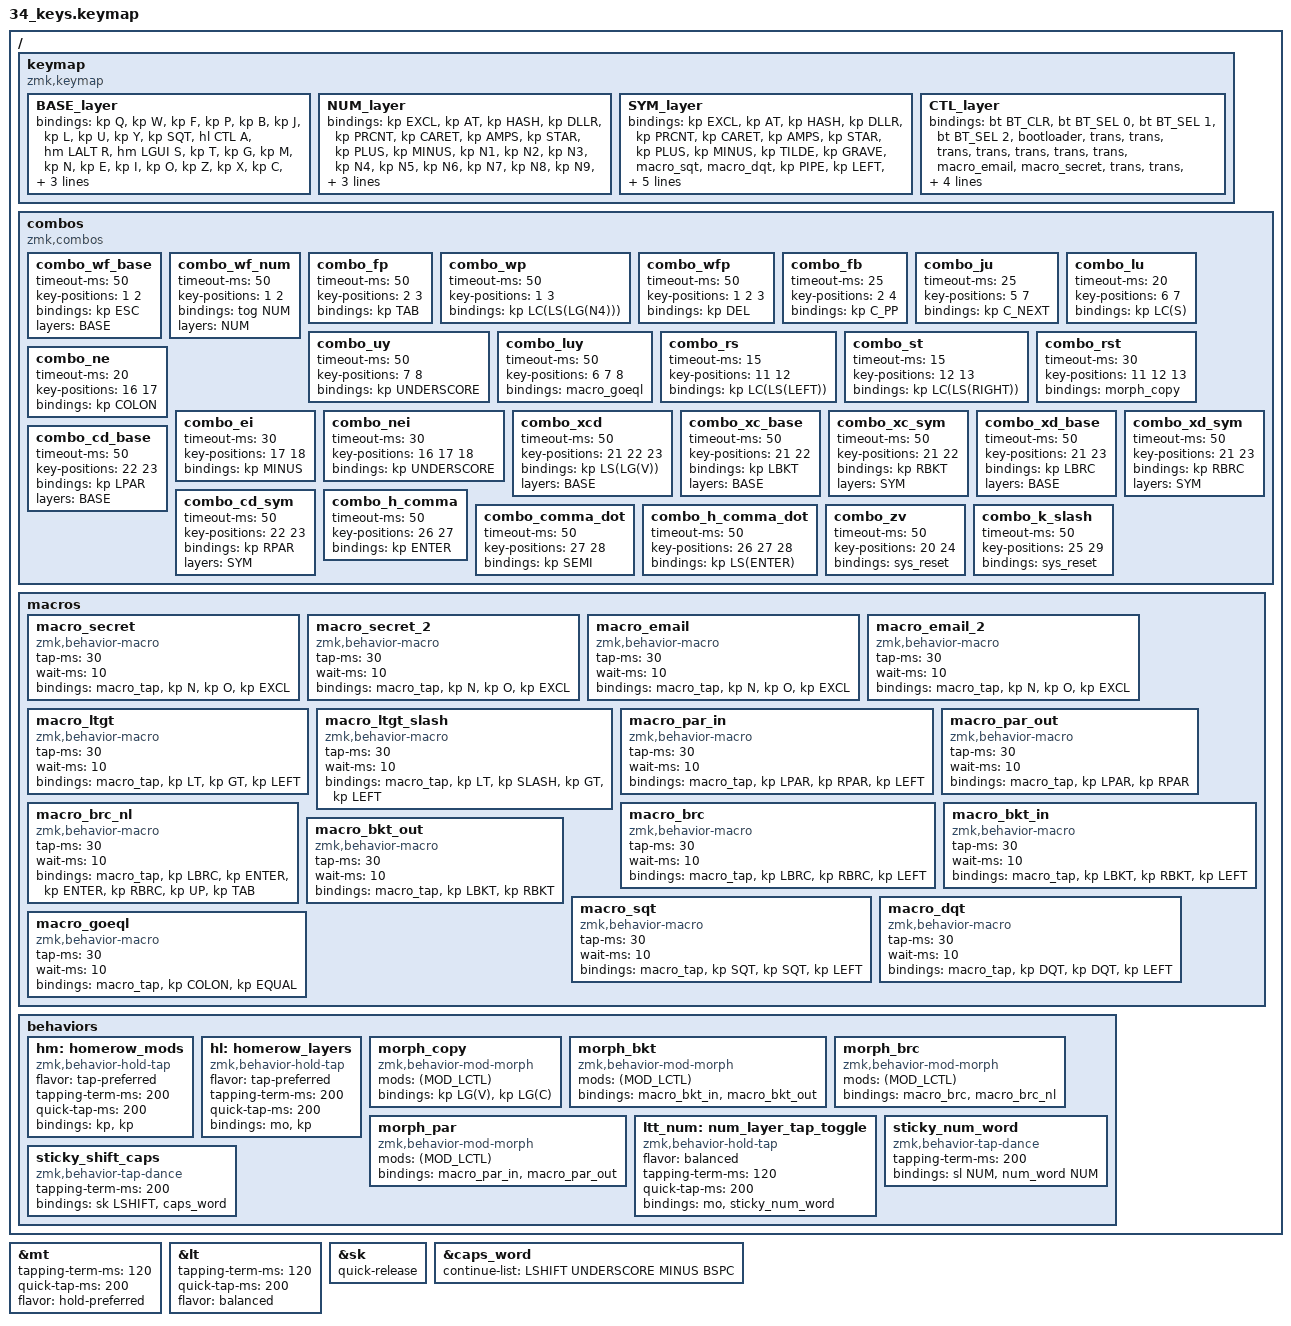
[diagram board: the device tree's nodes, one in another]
// vim: textwidth=0

/*
 * Copyright (c) 2021 The ZMK Contributors
 *
 * SPDX-License-Identifier: MIT
 */

#include <behaviors.dtsi>
#include <behaviors/num_word.dtsi>
#include <dt-bindings/zmk/keys.h>
#include <dt-bindings/zmk/bt.h>

#define BASE 0
#define NUM  1
#define SYM  2
#define CTL  3

&mt {
  tapping-term-ms = <120>;
  quick-tap-ms = <200>;
  flavor = "hold-preferred";
};

&lt {
  tapping-term-ms = <120>;
  quick-tap-ms = <200>;
  flavor = "balanced";
};

&sk {
  quick-release;  // prevent TWo caps when using sk SHIFT
};

&caps_word {
  continue-list = <LSHIFT UNDERSCORE MINUS BSPC>;
};

/*
30-key challenges
ctrl-z
shift-v -> solved by combo
ctrl-v -> not used often enough?
typing zmk lol
*/

/ {
  keymap {
    compatible = "zmk,keymap";

    BASE_layer {
      bindings = <
        // row 1
        &kp Q
        &kp W
        &kp F
        &kp P
        &kp B

        &kp J
        &kp L
        &kp U
        &kp Y
        &kp SQT

        // row 2
        &hl CTL A
        &hm LALT R
        &hm LGUI S
        &kp T
        &kp G

        &kp M
        &kp N
        &kp E
        &kp I
        &kp O

        // row 3
        &kp Z // dropped on 30-key
        &kp X
        &kp C
        &kp D
        &kp V // dropped on 30-key


        // &trans
        &kp K // dropped on 30-key
        &kp H
        &kp COMMA
        &kp DOT
        &kp SLASH // dropped on 30-key

        // row thumbs
        &sticky_shift_caps
        &mt LCTRL BSPC

        &lt SYM SPACE
        &ltt_num NUM NUM
      >;
    };

    NUM_layer {
      bindings = <
        // row 1
        &kp EXCL
        &kp AT
        &kp HASH
        &kp DLLR
        &kp PRCNT

        &kp CARET
        &kp AMPS
        &kp STAR
        &kp PLUS
        &kp MINUS

        // row 2
        &kp N1
        &kp N2
        &kp N3
        &kp N4
        &kp N5

        &kp N6
        &kp N7
        &kp N8
        &kp N9
        &kp N0

        // row 3
        &trans
        &trans
        &trans
        &trans
        &trans

        &trans
        &trans
        &trans
        &trans
        &trans

        // row thumbs
        &trans
        &trans
        &trans
        &trans // being held
      >;
    };

    SYM_layer {
      bindings = <
        // row 1
        &kp EXCL
        &kp AT
        &kp HASH
        &kp DLLR
        &kp PRCNT

        &kp CARET
        &kp AMPS
        &kp STAR
        &kp PLUS
        &kp MINUS

        // row 2
        &kp TILDE
        &kp GRAVE
        &macro_sqt
        &macro_dqt
        &kp PIPE

        &kp LEFT
        &kp DOWN
        &kp UP
        &kp RIGHT
        &kp BSLH

        // row 3
        &trans // dropped on 30-key
        &morph_bkt
        &morph_brc
        &morph_par
        &kp SEMI // dropped on 30-key

        &trans // dropped on 30-key
        &kp EQUAL
        &macro_ltgt
        &macro_ltgt_slash
        &trans // dropped on 30-key

        // row thumbs
        &trans
        &trans
        &trans // being held
        &trans
      >;
    };

    CTL_layer {
      bindings = <
        // row 1
        &bt BT_CLR
        &bt BT_SEL 0
        &bt BT_SEL 1
        &bt BT_SEL 2
        &bootloader

        &trans
        &trans
        &trans
        &trans
        &trans

        // row 2
        &trans
        &trans
        &macro_email
        &macro_secret
        &trans

        &trans
        &bt BT_PRV
        &bt BT_NXT
        &trans
        &trans

        // row 3
        &trans
        &trans
        &macro_email_2
        &macro_secret_2
        &trans

        &trans
        &trans
        &trans
        &trans
        &trans

        // row thumbs
        &trans
        &trans
        &trans
        &trans
      >;
    };
  };

  combos {
    compatible = "zmk,combos";
    // row 1
    combo_wf_base {
      timeout-ms = <50>;
      key-positions = <1 2>;
      bindings = <&kp ESC>;
      layers = <BASE>;
    };
    combo_wf_num {
      timeout-ms = <50>;
      key-positions = <1 2>;
      bindings = <&tog NUM>;
      layers = <NUM>;
    };
    combo_fp {
      timeout-ms = <50>;
      key-positions = <2 3>;
      bindings = <&kp TAB>;
    };
    combo_wp {
      timeout-ms = <50>;
      key-positions = <1 3>;
      bindings = <&kp LC(LS(LG(N4)))>; // screenshots
    };
    combo_wfp {
      timeout-ms = <50>;
      key-positions = <1 2 3>;
      bindings = <&kp DEL>;
    };
    combo_fb {
      timeout-ms = <25>;
      key-positions = <2 4>;
      bindings = <&kp C_PP>;
    };
    combo_ju {
      timeout-ms = <25>;
      key-positions = <5 7>;
      bindings = <&kp C_NEXT>;
    };
    combo_lu {
      timeout-ms = <20>;
      key-positions = <6 7>;
      bindings = <&kp LC(S)>;
    };
    combo_uy {
      timeout-ms = <50>;
      key-positions = <7 8>;
      bindings = <&kp UNDERSCORE>;
    };
    combo_luy {
      timeout-ms = <50>;
      key-positions = <6 7 8>;
      bindings = <&macro_goeql>;
    };
    // row 2
    combo_rs {
      timeout-ms = <15>;
      key-positions = <11 12>;
      bindings = <&kp LC(LS(LEFT))>;
    };
    combo_st {
      timeout-ms = <15>;
      key-positions = <12 13>;
      bindings = <&kp LC(LS(RIGHT))>;
    };
    combo_rst {
      timeout-ms = <30>;
      key-positions = <11 12 13>;
      bindings = <&morph_copy>;
    };
    combo_ne {
      timeout-ms = <20>;
      key-positions = <16 17>;
      bindings = <&kp COLON>;
    };
    combo_ei {
      timeout-ms = <30>;
      key-positions = <17 18>;
      bindings = <&kp MINUS>;
    };
    combo_nei {
      timeout-ms = <30>;
      key-positions = <16 17 18>;
      bindings = <&kp UNDERSCORE>;
    };
    // row 3
    combo_xcd { 
      timeout-ms = <50>;
      key-positions = <21 22 23>;
      bindings = <&kp LS(LG(V))>; // clipboard selection
      layers = <BASE>;
    };
    // singles of each [{()}]
    combo_xc_base {
      timeout-ms = <50>;
      key-positions = <21 22>;
      bindings = <&kp LBKT>;
      layers = <BASE>;
    };
    combo_xc_sym {
      timeout-ms = <50>;
      key-positions = <21 22>;
      bindings = <&kp RBKT>;
      layers = <SYM>;
    };
    combo_xd_base {
      timeout-ms = <50>;
      key-positions = <21 23>;
      bindings = <&kp LBRC>;
      layers = <BASE>;
    };
    combo_xd_sym {
      timeout-ms = <50>;
      key-positions = <21 23>;
      bindings = <&kp RBRC>;
      layers = <SYM>;
    };
    combo_cd_base {
      timeout-ms = <50>;
      key-positions = <22 23>;
      bindings = <&kp LPAR>;
      layers = <BASE>;
    };
    combo_cd_sym {
      timeout-ms = <50>;
      key-positions = <22 23>;
      bindings = <&kp RPAR>;
      layers = <SYM>;
    };
    combo_h_comma {
      timeout-ms = <50>;
      key-positions = <26 27>;
      bindings = <&kp ENTER>;
    };
    combo_comma_dot {
      timeout-ms = <50>;
      key-positions = <27 28>;
      bindings = <&kp SEMI>;
    };
    combo_h_comma_dot {
      timeout-ms = <50>;
      key-positions = <26 27 28>;
      bindings = <&kp LS(ENTER)>;
    };
    // resets
    combo_zv {
      timeout-ms = <50>;
      key-positions = <20 24>;
      bindings = <&sys_reset>;
    };
    combo_k_slash {
      timeout-ms = <50>;
      key-positions = <25 29>;
      bindings = <&sys_reset>;
    };
  };

  macros {
    macro_secret: macro_secret {
      compatible = "zmk,behavior-macro";
      tap-ms = <30>;
      wait-ms = <10>;
      #binding-cells = <0>;
      bindings = <&macro_tap &kp N &kp O &kp EXCL>;
    };
    macro_secret_2: macro_secret_2 {
      compatible = "zmk,behavior-macro";
      tap-ms = <30>;
      wait-ms = <10>;
      #binding-cells = <0>;
      bindings = <&macro_tap &kp N &kp O &kp EXCL>;
    };
    macro_email: macro_email {
      compatible = "zmk,behavior-macro";
      tap-ms = <30>;
      wait-ms = <10>;
      #binding-cells = <0>;
      bindings = <&macro_tap &kp N &kp O &kp EXCL>;
    };
    macro_email_2: macro_email_2 {
      compatible = "zmk,behavior-macro";
      tap-ms = <30>;
      wait-ms = <10>;
      #binding-cells = <0>;
      bindings = <&macro_tap &kp N &kp O &kp EXCL>;
    };
    macro_ltgt: macro_ltgt {
      compatible = "zmk,behavior-macro";
      tap-ms = <30>;
      wait-ms = <10>;
      #binding-cells = <0>;
      bindings = <&macro_tap &kp LT &kp GT &kp LEFT>;
    };
    macro_ltgt_slash: macro_ltgt_slash {
      compatible = "zmk,behavior-macro";
      tap-ms = <30>;
      wait-ms = <10>;
      #binding-cells = <0>;
      bindings = <&macro_tap &kp LT &kp SLASH &kp GT &kp LEFT>;
    };
    macro_par_in: macro_par_in {
      compatible = "zmk,behavior-macro";
      tap-ms = <30>;
      wait-ms = <10>;
      #binding-cells = <0>;
      bindings = <&macro_tap &kp LPAR &kp RPAR &kp LEFT>;
    };
    macro_par_out: macro_par_out {
      compatible = "zmk,behavior-macro";
      tap-ms = <30>;
      wait-ms = <10>;
      #binding-cells = <0>;
      bindings = <&macro_tap &kp LPAR &kp RPAR>;
    };
    macro_brc: macro_brc {
      compatible = "zmk,behavior-macro";
      tap-ms = <30>;
      wait-ms = <10>;
      #binding-cells = <0>;
      bindings = <&macro_tap &kp LBRC &kp RBRC &kp LEFT>;
    };
    macro_brc_nl: macro_brc_nl {
      compatible = "zmk,behavior-macro";
      tap-ms = <30>;
      wait-ms = <10>;
      #binding-cells = <0>;
      bindings = <&macro_tap &kp LBRC &kp ENTER &kp ENTER &kp RBRC &kp UP &kp TAB>;
    };
    macro_bkt_in: macro_bkt_in {
      compatible = "zmk,behavior-macro";
      tap-ms = <30>;
      wait-ms = <10>;
      #binding-cells = <0>;
      bindings = <&macro_tap &kp LBKT &kp RBKT &kp LEFT>;
    };
    macro_bkt_out: macro_bkt_out {
      compatible = "zmk,behavior-macro";
      tap-ms = <30>;
      wait-ms = <10>;
      #binding-cells = <0>;
      bindings = <&macro_tap &kp LBKT &kp RBKT>;
    };
    macro_sqt: macro_sqt {
      compatible = "zmk,behavior-macro";
      tap-ms = <30>;
      wait-ms = <10>;
      #binding-cells = <0>;
      bindings = <&macro_tap &kp SQT &kp SQT &kp LEFT>;
    };
    macro_dqt: macro_dqt {
      compatible = "zmk,behavior-macro";
      tap-ms = <30>;
      wait-ms = <10>;
      #binding-cells = <0>;
      bindings = <&macro_tap &kp DQT &kp DQT &kp LEFT>;
    };
    macro_goeql: macro_goeql {
      compatible = "zmk,behavior-macro";
      tap-ms = <30>;
      wait-ms = <10>;
      #binding-cells = <0>;
      bindings = <&macro_tap &kp COLON &kp EQUAL>;
    };
  };

  behaviors {
    hm: homerow_mods {
      compatible = "zmk,behavior-hold-tap";
      flavor = "tap-preferred";
      tapping-term-ms = <200>;
      quick-tap-ms = <200>;
      #binding-cells = <2>;
      bindings = <&kp>, <&kp>;
    };
    hl: homerow_layers {
      compatible = "zmk,behavior-hold-tap";
      flavor = "tap-preferred";
      tapping-term-ms = <200>;
      quick-tap-ms = <200>;
      #binding-cells = <2>;
      bindings = <&mo>, <&kp>;
    };
    morph_copy: morph_copy {
      compatible = "zmk,behavior-mod-morph";
      mods = <(MOD_LCTL)>;
      #binding-cells = <0>;
      bindings = <&kp LG(V)>, <&kp LG(C)>;
    };
    morph_bkt: morph_bkt {
      compatible = "zmk,behavior-mod-morph";
      mods = <(MOD_LCTL)>;
      #binding-cells = <0>;
      bindings = <&macro_bkt_in>, <&macro_bkt_out>;
    };
    morph_brc: morph_brc {
      compatible = "zmk,behavior-mod-morph";
      mods = <(MOD_LCTL)>;
      #binding-cells = <0>;
      bindings = <&macro_brc>, <&macro_brc_nl>;
    };
    morph_par: morph_par {
      compatible = "zmk,behavior-mod-morph";
      mods = <(MOD_LCTL)>;
      #binding-cells = <0>;
      bindings = <&macro_par_in>, <&macro_par_out>;
    };
    ltt_num: num_layer_tap_toggle {
      compatible = "zmk,behavior-hold-tap";
      flavor = "balanced";
      tapping-term-ms = <120>;
      quick-tap-ms = <200>;
      #binding-cells = <2>;
      bindings = <&mo>, <&sticky_num_word>;
    };
    sticky_num_word: sticky_num_word {
      compatible = "zmk,behavior-tap-dance";
      tapping-term-ms = <200>;
      #binding-cells = <0>;
      bindings = <&sl NUM>, <&num_word NUM>;
    };
    sticky_shift_caps: sticky_shift_caps {
      compatible = "zmk,behavior-tap-dance";
      tapping-term-ms = <200>;
      #binding-cells = <0>;
      bindings = <&sk LSHIFT>, <&caps_word>;
    };
  };
};


// NOTE: My dir are setup like
// - ~/code/zmk
// - ~/code/zmk-config
#include <../../../zmk-config/config/dont_commit_me.dtsi>
// this file might include something like
// &macro_secret {
//   bindings = <&macro_tap &kp S &kp H &kp H>;
// };
